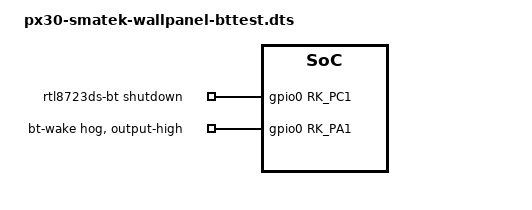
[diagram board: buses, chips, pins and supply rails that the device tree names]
// SPDX-License-Identifier: (GPL-2.0+ OR MIT)
/*
 * TEST VARIANT, not for production: Bluetooth via the vendor tool rtk_hciattach.
 *
 * Differences from px30-smatek-wallpanel.dts:
 *  - the bluetooth subnode under uart1 is gone, so hci_h5/btrtl do not bind
 *    and uart1 is available as a plain tty (/dev/ttyS1 via alias serial1);
 *  - BT-enable (GPIO0_C1) is driven by rfkill-gpio: "rfkill block/unblock
 *    bluetooth" resets the chip between two attempts;
 *  - BT-wake (GPIO0_A1) is held high by a gpio-hog.
 */
#include "px30-smatek-wallpanel.dts"

/ {
	aliases {
		serial1 = &uart1;
	};

	rfkill-bt {
		compatible = "rfkill-gpio";
		label = "rtl8723ds-bt";
		radio-type = "bluetooth";
		shutdown-gpios = <&gpio0 RK_PC1 GPIO_ACTIVE_HIGH>;
		pinctrl-names = "default";
		pinctrl-0 = <&bt_enable>;
	};
};

&gpio0 {
	bt-wake-hog {
		gpio-hog;
		gpios = <RK_PA1 GPIO_ACTIVE_HIGH>;
		output-high;
		line-name = "bt-wake";
	};
};

&uart1 {
	/delete-node/ bluetooth;
};
